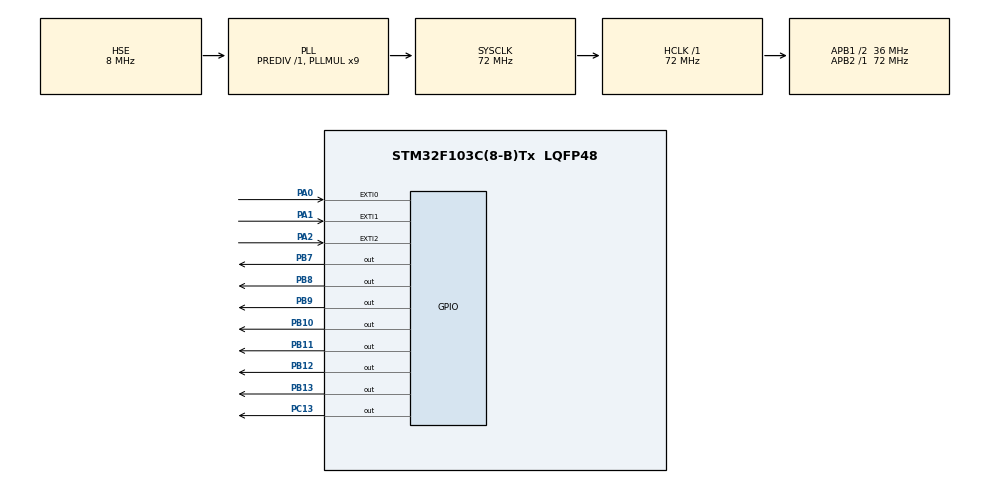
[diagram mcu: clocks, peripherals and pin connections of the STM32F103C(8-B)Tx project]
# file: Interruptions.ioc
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Mcu.Family=STM32F1
Mcu.Name=STM32F103C(8-B)Tx
Mcu.Package=LQFP48
NVIC.EXTI0_IRQn=true\:0\:0\:false\:false\:true\:true\:true\:true
NVIC.EXTI1_IRQn=true\:0\:0\:false\:false\:true\:true\:true\:true
NVIC.PriorityGroup=NVIC_PRIORITYGROUP_4
PA0-WKUP.GPIO_ModeDefaultEXTI=GPIO_MODE_IT_FALLING
PA0-WKUP.GPIO_PuPd=GPIO_PULLUP
PA0-WKUP.Signal=GPXTI0
PA1.GPIO_ModeDefaultEXTI=GPIO_MODE_IT_FALLING
PA1.GPIO_PuPd=GPIO_PULLUP
PA1.Signal=GPXTI1
PA13.Mode=Serial_Wire
PA13.Signal=SYS_JTMS-SWDIO
PA14.Mode=Serial_Wire
PA14.Signal=SYS_JTCK-SWCLK
PA2.GPIO_ModeDefaultEXTI=GPIO_MODE_IT_FALLING
PA2.GPIO_PuPd=GPIO_PULLUP
PA2.Signal=GPXTI2
PB10.Signal=GPIO_Output
PB11.Signal=GPIO_Output
PB12.Signal=GPIO_Output
PB13.Signal=GPIO_Output
PB7.Signal=GPIO_Output
PB8.Signal=GPIO_Output
PB9.Signal=GPIO_Output
PC13-TAMPER-RTC.Signal=GPIO_Output
PD0-OSC_IN.Mode=HSE-External-Oscillator
PD0-OSC_IN.Signal=RCC_OSC_IN
PD1-OSC_OUT.Mode=HSE-External-Oscillator
PD1-OSC_OUT.Signal=RCC_OSC_OUT
ProjectManager.HeapSize=0x200
ProjectManager.StackSize=0x400
ProjectManager.TargetToolchain=STM32CubeIDE
RCC.AHBFreq_Value=72000000
RCC.APB1CLKDivider=RCC_HCLK_DIV2
RCC.APB1Freq_Value=36000000
RCC.APB1TimFreq_Value=72000000
RCC.APB2Freq_Value=72000000
RCC.APB2TimFreq_Value=72000000
RCC.HCLKFreq_Value=72000000
RCC.PLLMUL=RCC_PLL_MUL9
RCC.PLLSourceVirtual=RCC_PLLSOURCE_HSE
RCC.SYSCLKFreq_VALUE=72000000
RCC.SYSCLKSource=RCC_SYSCLKSOURCE_PLLCLK
RCC.USBFreq_Value=72000000
board=custom

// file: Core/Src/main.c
/* USER CODE BEGIN Header */
/**
  ******************************************************************************
  * @file           : main.c
  * @brief          : Main program body
  ******************************************************************************
  * @attention
  *
  * Copyright (c) 2022 STMicroelectronics.
  * All rights reserved.
  *
  * This software is licensed under terms that can be found in the LICENSE file
  * in the root directory of this software component.
  * If no LICENSE file comes with this software, it is provided AS-IS.
  *
  ******************************************************************************
  */
/* USER CODE END Header */
#include "main.h"

/* USER CODE BEGIN PD */
#define flagInt2 (uint16_t) 0b100
/* USER CODE END PD */

/* USER CODE BEGIN PV */
uint32_t disp7segs[]={0x3f,0x06,0x5b,0x4f,0x66,0x6d,0x7d,0x07,0x7f,0x67};
int32_t valor=0;
/* USER CODE END PV */

void SystemClock_Config(void);
static void MX_GPIO_Init(void);
void borra(void);

int main(void)
{

  /* MCU Configuration--------------------------------------------------------*/

  /* Reset of all peripherals, Initializes the Flash interface and the Systick. */
  HAL_Init();

  /* Configure the system clock */
  SystemClock_Config();

  /* Initialize all configured peripherals */
  MX_GPIO_Init();
  /* USER CODE BEGIN 2 */
  GPIOB->ODR=disp7segs[valor]<<7;
  /* USER CODE END 2 */

  /* Infinite loop */
  while (1)
  {
	  //Polling es probar si el evento se genero probando la bandera
	  if ((flagInt2&EXTI->PR)!=0) {
		  borra();
	  }
  }
}

void SystemClock_Config(void)
{
  RCC_OscInitTypeDef RCC_OscInitStruct = {0};
  RCC_ClkInitTypeDef RCC_ClkInitStruct = {0};

  /** Initializes the RCC Oscillators according to the specified parameters
  * in the RCC_OscInitTypeDef structure.
  */
  RCC_OscInitStruct.OscillatorType = RCC_OSCILLATORTYPE_HSE;
  RCC_OscInitStruct.HSEState = RCC_HSE_ON;
  RCC_OscInitStruct.HSEPredivValue = RCC_HSE_PREDIV_DIV1;
  RCC_OscInitStruct.HSIState = RCC_HSI_ON;
  RCC_OscInitStruct.PLL.PLLState = RCC_PLL_ON;
  RCC_OscInitStruct.PLL.PLLSource = RCC_PLLSOURCE_HSE;
  RCC_OscInitStruct.PLL.PLLMUL = RCC_PLL_MUL9;
  if (HAL_RCC_OscConfig(&RCC_OscInitStruct) != HAL_OK)
  {
    Error_Handler();
  }

  /** Initializes the CPU, AHB and APB buses clocks
  */
  RCC_ClkInitStruct.ClockType = RCC_CLOCKTYPE_HCLK|RCC_CLOCKTYPE_SYSCLK
                              |RCC_CLOCKTYPE_PCLK1|RCC_CLOCKTYPE_PCLK2;
  RCC_ClkInitStruct.SYSCLKSource = RCC_SYSCLKSOURCE_PLLCLK;
  RCC_ClkInitStruct.AHBCLKDivider = RCC_SYSCLK_DIV1;
  RCC_ClkInitStruct.APB1CLKDivider = RCC_HCLK_DIV2;
  RCC_ClkInitStruct.APB2CLKDivider = RCC_HCLK_DIV1;

  if (HAL_RCC_ClockConfig(&RCC_ClkInitStruct, FLASH_LATENCY_2) != HAL_OK)
  {
    Error_Handler();
  }
}

static void MX_GPIO_Init(void)
{
  GPIO_InitTypeDef GPIO_InitStruct = {0};

  /* GPIO Ports Clock Enable */
  __HAL_RCC_GPIOC_CLK_ENABLE();
  __HAL_RCC_GPIOD_CLK_ENABLE();
  __HAL_RCC_GPIOA_CLK_ENABLE();
  __HAL_RCC_GPIOB_CLK_ENABLE();

  /*Configure GPIO pin Output Level */
  HAL_GPIO_WritePin(GPIOC, GPIO_PIN_13, GPIO_PIN_RESET);

  /*Configure GPIO pin Output Level */
  HAL_GPIO_WritePin(GPIOB, GPIO_PIN_10|GPIO_PIN_11|GPIO_PIN_12|GPIO_PIN_13
                          |GPIO_PIN_7|GPIO_PIN_8|GPIO_PIN_9, GPIO_PIN_RESET);

  /*Configure GPIO pin : PC13 */
  GPIO_InitStruct.Pin = GPIO_PIN_13;
  GPIO_InitStruct.Mode = GPIO_MODE_OUTPUT_PP;
  GPIO_InitStruct.Pull = GPIO_NOPULL;
  GPIO_InitStruct.Speed = GPIO_SPEED_FREQ_LOW;
  HAL_GPIO_Init(GPIOC, &GPIO_InitStruct);

  /*Configure GPIO pins : PA0 PA1 PA2 */
  GPIO_InitStruct.Pin = GPIO_PIN_0|GPIO_PIN_1|GPIO_PIN_2;
  GPIO_InitStruct.Mode = GPIO_MODE_IT_FALLING;
  GPIO_InitStruct.Pull = GPIO_PULLUP;
  HAL_GPIO_Init(GPIOA, &GPIO_InitStruct);

  /*Configure GPIO pins : PB10 PB11 PB12 PB13
                           PB7 PB8 PB9 */
  GPIO_InitStruct.Pin = GPIO_PIN_10|GPIO_PIN_11|GPIO_PIN_12|GPIO_PIN_13
                          |GPIO_PIN_7|GPIO_PIN_8|GPIO_PIN_9;
  GPIO_InitStruct.Mode = GPIO_MODE_OUTPUT_PP;
  GPIO_InitStruct.Pull = GPIO_NOPULL;
  GPIO_InitStruct.Speed = GPIO_SPEED_FREQ_LOW;
  HAL_GPIO_Init(GPIOB, &GPIO_InitStruct);

  /* EXTI interrupt init*/
  HAL_NVIC_SetPriority(EXTI0_IRQn, 0, 0);
  HAL_NVIC_EnableIRQ(EXTI0_IRQn);

  HAL_NVIC_SetPriority(EXTI1_IRQn, 0, 0);
  HAL_NVIC_EnableIRQ(EXTI1_IRQn);

}

/* USER CODE BEGIN 4 */
void HAL_GPIO_EXTI_Callback(uint16_t GPIO_Pin) {
	//HAL_GPIO_TogglePin(GPIOC, GPIO_PIN_13);
	// Program 2
	/*
	for (uint32_t i; i < 400000; i++) {} //Un retardo
	if (GPIO_Pin==GPIO_PIN_0) valor++; //Check if interruption occurred in port 0
	if (GPIO_Pin==GPIO_PIN_1) valor--;
	if (valor>9) valor=0;
	if (valor==-1) valor=9;
	GPIOB->ODR=disp7segs[valor]<<7; */

	// Program 3
	if (GPIO_Pin==GPIO_PIN_0) valor++;
	if (GPIO_Pin==GPIO_PIN_1) valor--;
	if (valor>9) valor=0;
	if (valor==-1) valor=9;
	GPIOB->ODR=disp7segs[valor]<<7;
}

void borra(void)
{
EXTI->PR=flagInt2; //Borra bandera
valor=0;
GPIOB->ODR=disp7segs[valor]<<7;
}
/* USER CODE END 4 */

void Error_Handler(void)
{
  __disable_irq();
  while (1)
  {
  }
}
